# M3V4 register map
File version: 0.1
Registers are 32-bit, read-write, reset 0x0 unless marked. A register's access mark holds for its fields unless they carry their own. Offsets are from the block's base; [hi:lo] are bit positions; {n}, {i} and the like mark numbered series.

## WD — Watchdog Timer (WD)
Base 0x40040000
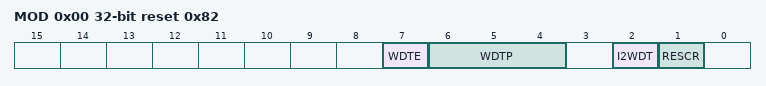
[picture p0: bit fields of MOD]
0x00 MOD reset 0x82 — WD Mode Register
  [7] WDTE, [6:4] WDTP, [2] I2WDT, [1] RESCR
0x04 CR wo (reset mask 0xFFFFFF00) — WD Control Register
  [7:0] WDCR

## RTC — Real Time Clock (RTC)
Base 0x40040100
0x00 SECR 8-bit (reset mask 0x80) — RTC Second Column Register
  [6:0] SE
0x01 MINR 8-bit (reset mask 0x80) — RTC Minute Column Register
  [6:0] MI
0x02 HOURR 8-bit (reset mask 0xC0) — RTC Hour Column Register
  [5:0] HO
0x04 DAYR 8-bit (reset mask 0xF8) — RTC Day of the Week Column Register
  [2:0] WE
0x05 DATER 8-bit (reset mask 0xC0) — RTC Day Column Register
  [5:0] DA
0x06 MONTHR_A 8-bit (reset mask 0xE0) — RTC Month Column Register
  [4:0] MO
0x06 MONTHR_B 8-bit (reset mask 0xFE) (RTC_MONTHR view) — RTC Month Column Register
  [0] MO0
0x07 YEARR_A 8-bit reset not defined — RTC Year Column Register
  [7:0] YE
0x07 YEARR_B 8-bit (reset mask 0xFC) (RTC_YEARR view) — RTC Year Column Register
  [1:0] LEAP
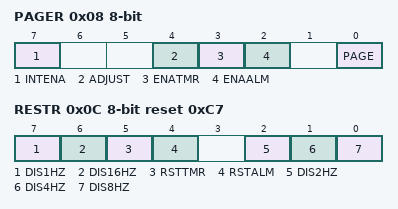
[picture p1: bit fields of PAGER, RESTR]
0x08 PAGER 8-bit (reset mask 0xF3) — RTC PAGE Register
  [7] INTENA, [4] ADJUST, [3] ENATMR, [2] ENAALM, [0] PAGE
0x0C RESTR 8-bit reset 0xC7 — RTC Reset Register
  [7] DIS1HZ, [6] DIS16HZ, [5] RSTTMR, [4] RSTALM, [2] DIS2HZ, [1] DIS4HZ, [0] DIS8HZ

## CG — Clock Generator (CG)
Base 0x40040200
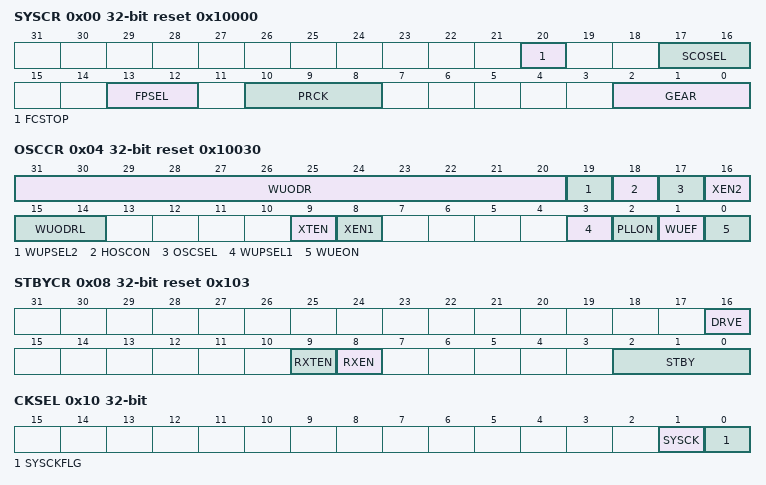
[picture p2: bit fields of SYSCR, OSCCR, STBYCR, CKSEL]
0x00 SYSCR reset 0x10000 — System Control Register
  [20] FCSTOP, [17:16] SCOSEL, [13:12] FPSEL, [10:8] PRCK, [2:0] GEAR
0x04 OSCCR reset 0x10030 — Oscillation Control Register
  [31:20] WUODR, [19] WUPSEL2, [18] HOSCON, [17] OSCSEL, [16] XEN2, [15:14] WUODRL, [9] XTEN, [8] XEN1, [3] WUPSEL1, [2] PLLON, [1] WUEF ro, [0] WUEON wo
0x08 STBYCR reset 0x103 — Standby Control Register
  [16] DRVE, [9] RXTEN, [8] RXEN, [2:0] STBY
0x0C PLLSEL reset 0x721E — PLL Selection Register
  [0] PLLSEL
0x10 CKSEL — System Clock Selection Register
  [1] SYSCK, [0] SYSCKFLG ro
0x14 ICRCG wo — CG Interrupt Request Clear Register
  [4:0] ICRCG
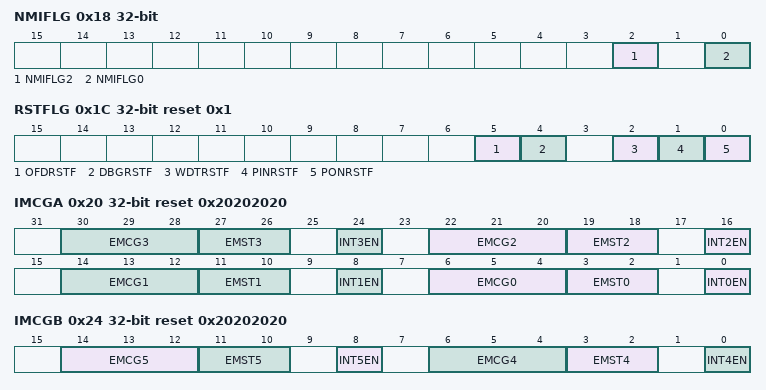
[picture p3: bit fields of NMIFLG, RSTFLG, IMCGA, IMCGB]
0x18 NMIFLG ro — NMI Flag Register
  [2] NMIFLG2, [0] NMIFLG0
0x1C RSTFLG reset 0x1 — Reset Flag Register
  [5] OFDRSTF, [4] DBGRSTF, [2] WDTRSTF, [1] PINRSTF, [0] PONRSTF
0x20 IMCGA reset 0x20202020 — CG Interrupt Mode Control Register A
  [8n+6:8n+4] EMCG{n} (n=0..3), [8n+3:8n+2] EMST{n} ro (n=0..3), [8n] INT{n}EN (n=0..3)
0x24 IMCGB reset 0x20202020 — CG Interrupt Mode Control Register B
  [14:12] EMCG5, [11:10] EMST5 ro, [8] INT5EN, [6:4] EMCG4, [3:2] EMST4 ro, [0] INT4EN
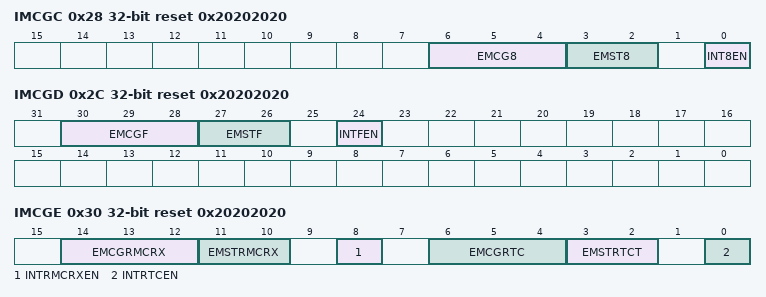
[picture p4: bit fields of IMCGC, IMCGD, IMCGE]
0x28 IMCGC reset 0x20202020 — CG Interrupt Mode Control Register C
  [6:4] EMCG8, [3:2] EMST8 ro, [0] INT8EN
0x2C IMCGD reset 0x20202020 — CG Interrupt Mode Control Register D
  [30:28] EMCGF, [27:26] EMSTF ro, [24] INTFEN
0x30 IMCGE reset 0x20202020 — CG Interrupt Mode Control Register E
  [14:12] EMCGRMCRX, [11:10] EMSTRMCRX ro, [8] INTRMCRXEN, [6:4] EMCGRTC, [3:2] EMSTRTCT ro, [0] INTRTCEN

## RMC — Remote Control Signal Preprocessor (RMC)
Base 0x40040400
0x00 EN — RMC Enable Register
  [0] RMCEN
0x04 REN — RMC Receive Enable Register
  [0] RMCREN
0x08 RBUF1 ro — RMC Receive Data Buffer Register 1
  [31:0] RMCRBUF
0x0C RBUF2 ro — RMC Receive Data Buffer Register 2
  [31:0] RMCRBUF
0x10 RBUF3 ro — RMC Receive Data Buffer Register 3
  [7:0] RMCRBUF
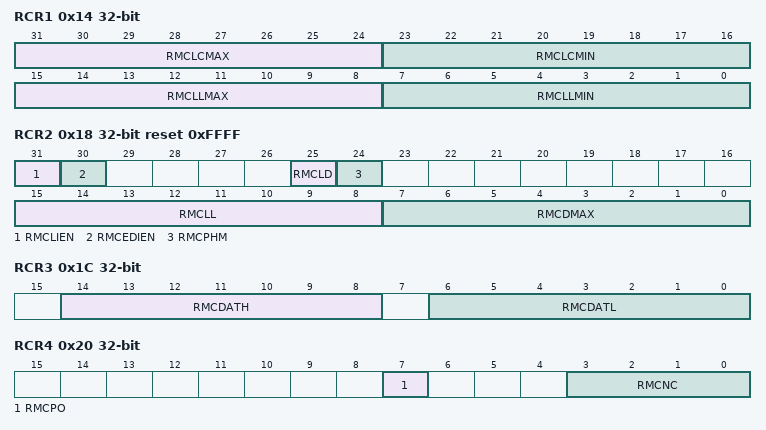
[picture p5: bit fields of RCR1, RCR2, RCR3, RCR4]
0x14 RCR1 — RMC Receive Control Register 1
  [31:24] RMCLCMAX, [23:16] RMCLCMIN, [15:8] RMCLLMAX, [7:0] RMCLLMIN
0x18 RCR2 reset 0xFFFF — RMC Receive Control Register 2
  [31] RMCLIEN, [30] RMCEDIEN, [25] RMCLD, [24] RMCPHM, [15:8] RMCLL, [7:0] RMCDMAX
0x1C RCR3 — RMC Receive Control Register 3
  [14:8] RMCDATH, [6:0] RMCDATL
0x20 RCR4 — RMC Receive Control Register 4
  [7] RMCPO, [3:0] RMCNC
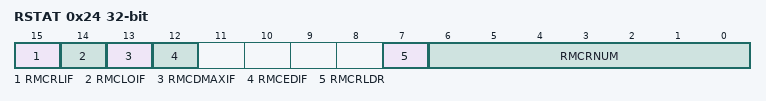
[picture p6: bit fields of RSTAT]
0x24 RSTAT ro — RMC Receive Status Register
  [15] RMCRLIF, [14] RMCLOIF, [13] RMCDMAXIF, [12] RMCEDIF, [7] RMCRLDR, [6:0] RMCRNUM
{0x24+4i} END{i} (i=1..3) — RMC Receive End Bit Number Register {i}
  [6:0] RMCEND{i}
0x34 FSSEL — RMC Frequency Selection Register
  [0] RMCCLK

## OFD — Oscillation Frequency Detector (OFD)
Base 0x40040800
0x00 CR1 reset 0x6 — OFD Control Register 1
  [7:0] OFDWEN
0x04 CR2 — OFD Control Register 2
  [7:0] OFDEN
0x08 MN — OFD Lower Detection Frequency Setting Register
  [7:0] OFDMN
0x10 MX — OFD Higher Detection Frequency Setting Register
  [7:0] OFDMX
0x18 RST reset 0x1 — OFD Reset Enable Control Register
  [0] OFDRSTEN
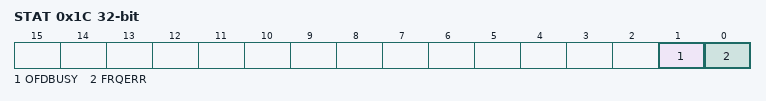
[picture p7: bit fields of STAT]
0x1C STAT ro — OFD Status Register
  [1] OFDBUSY, [0] FRQERR

## VD — Voltage Detection Circuit (VD)
Base 0x40040900
0x00 CR reset 0x2 — Voltage Detection Control Register
  [0] VDEN

## NF — DigitalNoizeFilterClockControl
Base 0x40060000
0x00 CKCR — Clcok Control
  [2:0] NFCKS
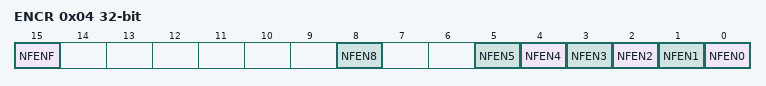
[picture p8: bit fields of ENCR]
0x04 ENCR — EnableControl
  [15] NFENF, [8] NFEN8, [n] NFEN{n} (n=0..5)

## SSP — Synchronous Serial Port (SSP)
Base 0x400C0000
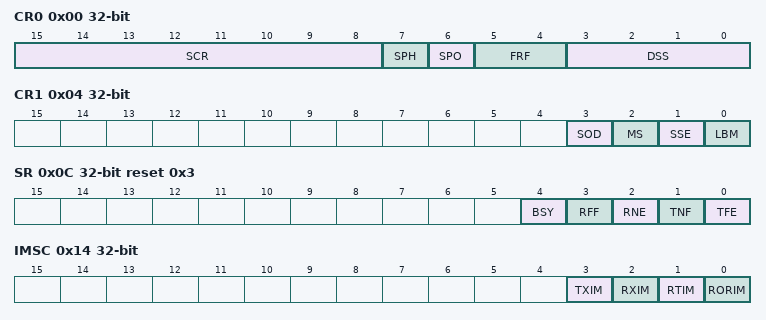
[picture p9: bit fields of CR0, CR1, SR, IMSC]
0x00 CR0 — SSP Control Register 0
  [15:8] SCR, [7] SPH, [6] SPO, [5:4] FRF, [3:0] DSS
0x04 CR1 — SSP Control Register 1
  [3] SOD, [2] MS, [1] SSE, [0] LBM
0x08 DR — SSP Data Register
  [15:0] DATA
0x0C SR ro reset 0x3 — SSP Status Register
  [4] BSY, [3] RFF, [2] RNE, [1] TNF, [0] TFE
0x10 CPSR — SSP Clock Prescaler Register
  [7:0] CPSDVSR
0x14 IMSC — SSP Interrupt Mask Set and Clear Register
  [3] TXIM, [2] RXIM, [1] RTIM, [0] RORIM
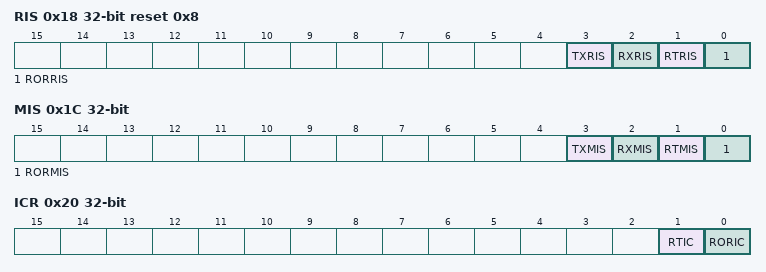
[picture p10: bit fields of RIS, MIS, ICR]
0x18 RIS ro reset 0x8 — SSP Raw Interrupt Status Register
  [3] TXRIS, [2] RXRIS, [1] RTRIS, [0] RORRIS
0x1C MIS ro — SSP Masked Interrupt Status Register
  [3] TXMIS, [2] RXMIS, [1] RTMIS, [0] RORMIS
0x20 ICR wo reset not defined — SSP Interrupt Clear Register
  [1] RTIC, [0] RORIC

## UART
Base 0x400C2000
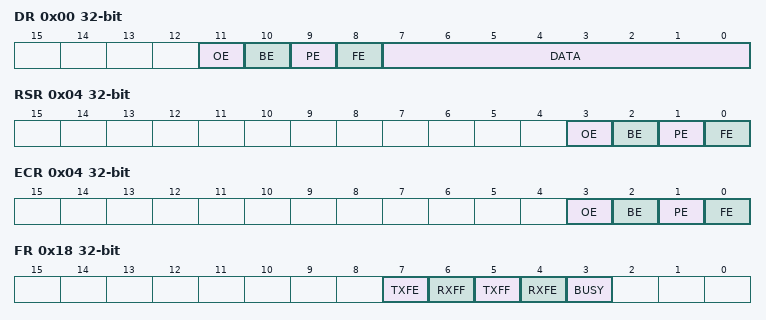
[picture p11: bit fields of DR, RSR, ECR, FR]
0x00 DR — Data Register
  [11] OE ro, [10] BE ro, [9] PE ro, [8] FE ro, [7:0] DATA
0x04 RSR ro — Receive Status Register
  [3] OE, [2] BE, [1] PE, [0] FE
0x04 ECR wo — Error Clear Register
  [3] OE, [2] BE, [1] PE, [0] FE
0x18 FR ro — Flag Register
  [7] TXFE, [6] RXFF, [5] TXFF, [4] RXFE, [3] BUSY
0x24 IBRD — Integer Baud Rate Register
  [15:0] BAUDDIVINT
0x28 FBRD — Fractional Baud Rate Register
  [5:0] BAUDDIVFRAC
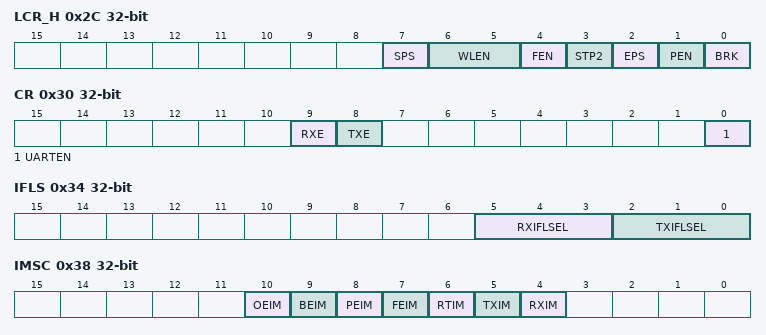
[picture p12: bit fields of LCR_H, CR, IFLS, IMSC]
0x2C LCR_H — Line Control Register
  [7] SPS, [6:5] WLEN, [4] FEN, [3] STP2, [2] EPS, [1] PEN, [0] BRK
0x30 CR — Control Register
  [9] RXE, [8] TXE, [0] UARTEN
0x34 IFLS — Interrupt FIFO Level Selection Register
  [5:3] RXIFLSEL, [2:0] TXIFLSEL
0x38 IMSC — Interrupt Mask Set_Clear Register
  [10] OEIM, [9] BEIM, [8] PEIM, [7] FEIM, [6] RTIM, [5] TXIM, [4] RXIM
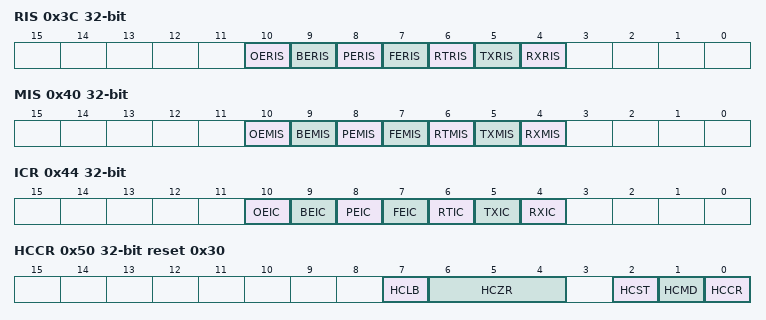
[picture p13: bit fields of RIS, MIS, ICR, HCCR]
0x3C RIS ro — Raw Interrupt Status Register
  [10] OERIS, [9] BERIS, [8] PERIS, [7] FERIS, [6] RTRIS, [5] TXRIS, [4] RXRIS
0x40 MIS ro — Masked Interrupt Status Register
  [10] OEMIS, [9] BEMIS, [8] PEMIS, [7] FEMIS, [6] RTMIS, [5] TXMIS, [4] RXMIS
0x44 ICR wo — Interrupt Clear Register
  [10] OEIC, [9] BEIC, [8] PEIC, [7] FEIC, [6] RTIC, [5] TXIC, [4] RXIC
0x50 HCCR reset 0x30 — HC Control Register
  [7] HCLB, [6:4] HCZR, [2] HCST, [1] HCMD, [0] HCCR

## FC — Flash Control (FC)
Base 0x41FFF000
0x10 SECBIT reset 0x1 — FC Security Bit Register
  [0] SECBIT
0x1C CR — Flash Interface Control Register
  [0] FLBOFF
0x20 SR ro reset 0x1 — FC FLASH Control Register
  [0] RDY_BSY
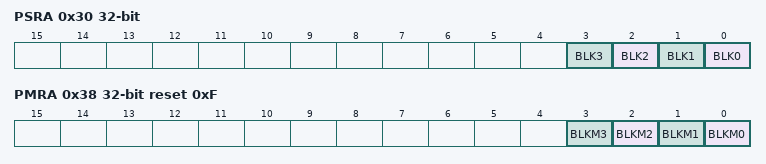
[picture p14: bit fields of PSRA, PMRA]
0x30 PSRA ro (reset mask 0xFFFFFFF0) — FC Protect status register
  [n] BLK{n} (n=0..3)
0x38 PMRA reset 0xF — FC Protect Mask register
  [n] BLKM{n} (n=0..3)
